# LPC11E6x register map
File version: 0.8
CPU: CM0PLUS r0p1, little endian, no MPU, no FPU, 0x2 interrupt priority bits, 0x0 interrupts
Registers are 32-bit, read-write, reset 0x0 unless marked. A register's access mark holds for its fields unless they carry their own. Offsets are from the block's base; [hi:lo] are bit positions; {n}, {i} and the like mark numbered series.

## SCT0 — State Configurable Timers (SCTimer/PWM)
Base 0x5000C000
Same registers: SCT1 0x5000E000
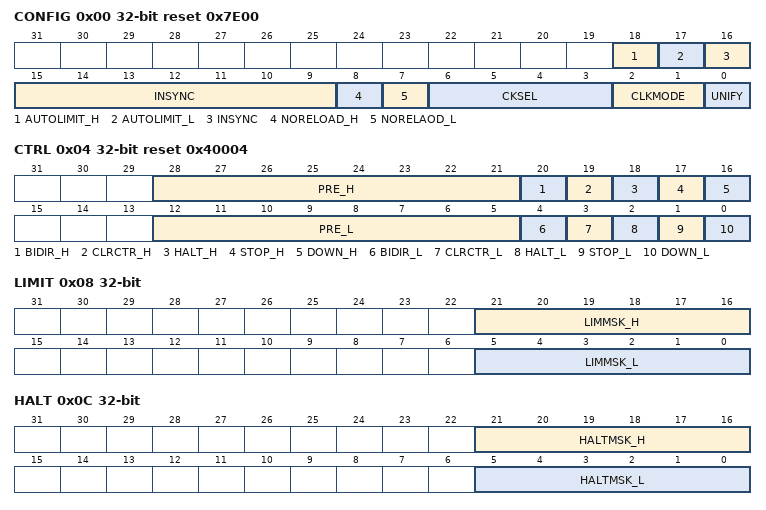
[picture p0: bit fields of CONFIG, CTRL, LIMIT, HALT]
0x00 CONFIG reset 0x7E00 — SCT configuration register
  [18] AUTOLIMIT_H — A one in this bit will cause a match on match register 0 to be treated as a de-facto LIMIT condition without the need to define an associated event. As with any LIMIT event, this automatic limit causes the counter to be cleared to zero in uni-directional mode or to change the direction of count in bi-directional mode. Software can write to set or clear this bit at any time. This bit is not used when the UNIFY bit is set.
  [17] AUTOLIMIT_L — A one in this bit causes a match on match register 0 to be treated as a de-facto LIMIT condition without the need to define an associated event. As with any LIMIT event, this automatic limit causes the counter to be cleared to zero in uni-directional mode or to change the direction of count in bi-directional mode. Software can write to set or clear this bit at any time. This bit applies to both the higher and lower registers when the UNIFY bit is set.
  [16:9] INSYNC — Synchronization for input N (bit 9 = input 0, bit 10 = input 1,..., bit 12 = input 3); all other bits are reserved. A 1 in one of these bits subjects the corresponding input to synchronization to the SCT clock, before it is used to create an event. If an input is synchronous to the SCT clock, keep its bit 0 for faster response. When the CKMODE field is 1x, the bit in this field, corresponding to the input selected by the CKSEL field, is not used.
  [8] NORELOAD_H — A 1 in this bit prevents the higher match registers from being reloaded from their respective reload registers. Software can write to set or clear this bit at any time. This bit is not used when the UNIFY bit is set.
  [7] NORELAOD_L — A 1 in this bit prevents the lower match registers from being reloaded from their respective reload registers. Software can write to set or clear this bit at any time. This bit applies to both the higher and lower registers when the UNIFY bit is set.
  [6:3] CKSEL — SCT clock select
    0=RISING_EDGES_ON_INPU (Rising edges on input 0.); 1=FALLING_EDGES_ON_INP (Falling edges on input 0.); 2=RISING_EDGES_ON_INPU (Rising edges on input 1.); 3=FALLING_EDGES_ON_INP (Falling edges on input 1.); 4=RISING_EDGES_ON_INPU (Rising edges on input 2.); 5=FALLING_EDGES_ON_INP (Falling edges on input 2.); 6=RISING_EDGES_ON_INPU (Rising edges on input 3.); 7=FALLING_EDGES_ON_INP (Falling edges on input 3.)
  [2:1] CLKMODE — SCT clock mode
    0=THE_BUS_CLOCK_CLOCKS (The bus clock clocks the SCT and prescalers.); 1=THE_SCT_CLOCK_IS_THE (The SCT clock is the bus clock, but the prescalers are enabled to count only when sampling of the input selected by the CKSEL field finds the selected edge. The minimum pulse width on the clock input is 1 bus clock period. This mode is the high-performance sampled-clock mode.); 2=THE_INPUT_SELECTED_B (The input selected by CKSEL clocks the SCT and prescalers. The input is synchronized to the bus clock and possibly inverted. The minimum pulse width on the clock input is 1 bus clock period. This mode is the low-power sampled-clock mode.); 3=PRESCALED_SCT_INPUT (Prescaled SCT input. The SCT and prescalers are clocked by the input edge selected by the CKSEL field. In this mode, most of the SCT is clocked by the (selected polarity of the) input. The outputs are switched synchronously to the input clock. The input clock rate must be at least half the system clock rate and can the same or faster than the system clock.)
  [0] UNIFY — SCT operation
    0=THE_SCT_OPERATES_AS (The SCT operates as two 16-bit counters named L and H.); 1=THE_SCT_OPERATES_AS (The SCT operates as a unified 32-bit counter.)
0x04 CTRL reset 0x40004 — SCT control register
  [28:21] PRE_H — Specifies the factor by which the SCT clock is prescaled to produce the H counter clock. The counter clock is clocked at the rate of the SCT clock divided by PRELH+1. Clear the counter (by writing a 1 to the CLRCTR bit) whenever changing the PRE value.
  [20] BIDIR_H — Direction select
    0=THE_H_COUNTER_COUNTS (The H counter counts up to its limit condition, then is cleared to zero.); 1=THE_H_COUNTER_COUNTS (The H counter counts up to its limit, then counts down to a limit condition or to 0.)
  [19] CLRCTR_H — Writing a 1 to this bit clears the H counter. This bit always reads as 0.
  [18] HALT_H — When this bit is 1, the H counter does not run and no events can occur. A reset sets this bit. When the HALT_H bit is one, the STOP_H bit is cleared. If you want to remove the halt condition and keep the SCT in the stop condition (not running), then you can change the halt and stop condition with one single write to this register. Once set, this bit can only be cleared by software to restore counter operation.
  [17] STOP_H — When this bit is 1 and HALT is 0, the H counter does not, run but I/O events related to the counter can occur. If such an event matches the mask in the Start register, this bit is cleared and counting resumes.
  [16] DOWN_H — This bit is 1 when the H counter is counting down. Hardware sets this bit when the counter limit is reached and BIDIR is 1. Hardware clears this bit when the counter is counting down and a limit condition occurs or when the counter reaches 0.
  [12:5] PRE_L — Specifies the factor by which the SCT clock is prescaled to produce the L or unified counter clock. The counter clock is clocked at the rate of the SCT clock divided by PRE_L+1. Clear the counter (by writing a 1 to the CLRCTR bit) whenever changing the PRE value.
  [4] BIDIR_L — L or unified counter direction select
    0=THE_COUNTER_COUNTS_U (The counter counts up to its limit condition, then is cleared to zero.); 1=THE_COUNTER_COUNTS_U (The counter counts up to its limit, then counts down to a limit condition or to 0.)
  [3] CLRCTR_L — Writing a 1 to this bit clears the L or unified counter. This bit always reads as 0.
  [2] HALT_L — When this bit is 1, the L or unified counter does not run and no events can occur. A reset sets this bit. When the HALT_L bit is one, the STOP_L bit is cleared. If you want to remove the halt condition and keep the SCT in the stop condition (not running), then you can change the halt and stop condition with one single write to this register. Once set, only software can clear this bit to restore counter operation.
  [1] STOP_L — When this bit is 1 and HALT is 0, the L or unified counter does not run, but I/O events related to the counter can occur. If such an event matches the mask in the Start register, this bit is cleared and counting resumes.
  [0] DOWN_L — This bit is 1 when the L or unified counter is counting down. Hardware sets this bit when the counter limit is reached and BIDIR is 1. Hardware clears this bit when the counter is counting down and a limit condition occurs or when the counter reaches 0.
0x08 LIMIT — SCT limit register
  [21:16] LIMMSK_H — If bit n is one, event n is used as a counter limit for the H counter (event 0 = bit 16, event 1 = bit 17, event 5 = bit 21).
  [5:0] LIMMSK_L — If bit n is one, event n is used as a counter limit for the L or unified counter (event 0 = bit 0, event 1 = bit 1, event 5 = bit 5).
0x0C HALT — SCT halt condition register
  [21:16] HALTMSK_H — If bit n is one, event n sets the HALT_H bit in the CTRL register (event 0 = bit 16, event 1 = bit 17, event 5 = bit 21).
  [5:0] HALTMSK_L — If bit n is one, event n sets the HALT_L bit in the CTRL register (event 0 = bit 0, event 1 = bit 1, event 5 = bit 5).
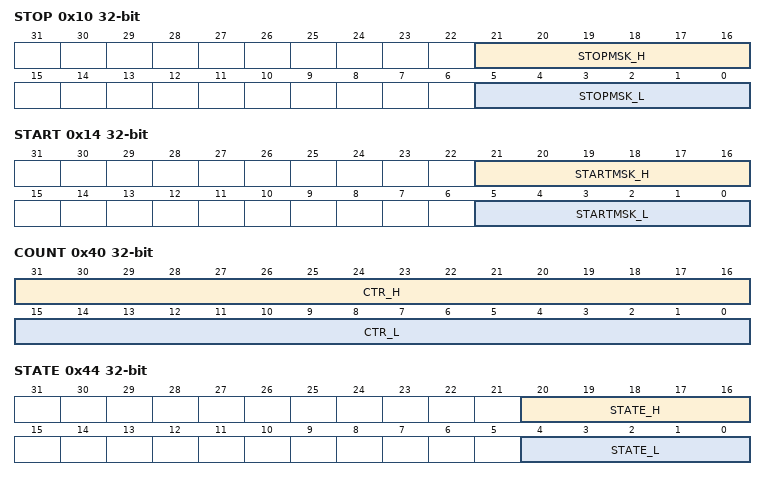
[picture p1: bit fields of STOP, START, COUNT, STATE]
0x10 STOP — SCT stop condition register
  [21:16] STOPMSK_H — If bit n is one, event n sets the STOP_H bit in the CTRL register (event 0 = bit 16, event 1 = bit 17, event 5 = bit 21).
  [5:0] STOPMSK_L — If bit n is one, event n sets the STOP_L bit in the CTRL register (event 0 = bit 0, event 1 = bit 1, event 5 = bit 5).
0x14 START — SCT start condition register
  [21:16] STARTMSK_H — If bit n is one, event n clears the STOP_H bit in the CTRL register (event 0 = bit 16, event 1 = bit 17, event 5 = bit 21).
  [5:0] STARTMSK_L — If bit n is one, event n clears the STOP_L bit in the CTRL register (event 0 = bit 0, event 1 = bit 1, event 5 = bit 5).
0x40 COUNT — SCT counter register
  [31:16] CTR_H — When UNIFY = 0, read or write the 16-bit H counter value. When UNIFY = 1, read or write the upper 16 bits of the 32-bit unified counter.
  [15:0] CTR_L — When UNIFY = 0, read or write the 16-bit L counter value. When UNIFY = 1, read or write the lower 16 bits of the 32-bit unified counter.
0x44 STATE — SCT state register
  [20:16] STATE_H — State variable.
  [4:0] STATE_L — State variable.
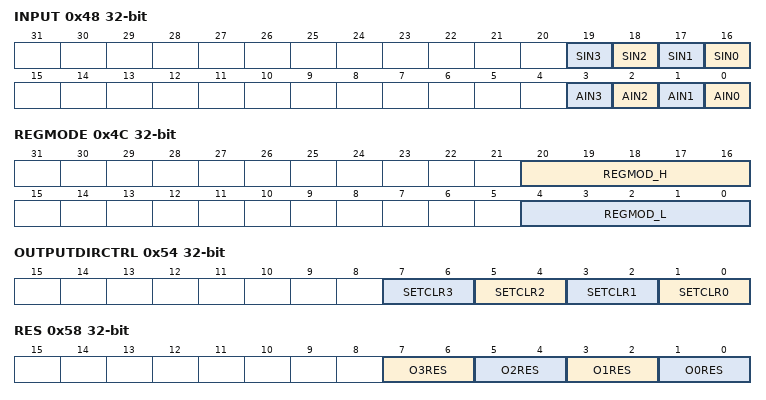
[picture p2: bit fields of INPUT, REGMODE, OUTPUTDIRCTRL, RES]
0x48 INPUT ro — SCT input register
  [n+16] SIN{n} (n=0..3) — Input {n} state synchronized to the SCT clock.
  [n] AIN{n} (n=0..3) — Real-time status of input {n}.
0x4C REGMODE — SCT match/capture registers mode register
  [20:16] REGMOD_H — Each bit controls one pair of match/capture registers (register 0 = bit 16, register 1 = bit 17,..., register 4 = bit 20). 0 = registers operate as match registers. 1 = registers operate as capture registers.
  [4:0] REGMOD_L — Each bit controls one pair of match/capture registers (register 0 = bit 0, register 1 = bit 1,..., register 4 = bit 4). 0 = registers operate as match registers. 1 = registers operate as capture registers.
0x50 OUTPUT — SCT output register
  [3:0] OUT — Writing a 1 to bit n makes the corresponding output HIGH. 0 makes the corresponding output LOW (output 0 = bit 0, output 1 = bit 1,..., output 3 = bit 3).
0x54 OUTPUTDIRCTRL — SCT output counter direction control register
  [all] fields
    0=SET_AND_CLEAR_DO_NOT (Set and clear do not depend on any counter.); 1=SET_AND_CLEAR_ARE_RE (Set and clear are reversed when counter L or the unified counter is counting down.); 2=SET_AND_CLEAR_ARE_RE (Set and clear are reversed when counter H is counting down. Do not use if UNIFY = 1.)
  [2n+1:2n] SETCLR{n} (n=0..3) — Set/clear operation on output {n}. Value 0x3 is reserved. Do not program this value.
0x58 RES — SCT conflict resolution register
  [7:6] O3RES — Effect of simultaneous set and clear on output 3.
    0=NO_CHANGE; 1=SET_OUTPUT_OR_CLEAR (Set output (or clear based on the SETCLR3 field).); 2=CLEAR_OUTPUT_OR_SET (Clear output (or set based on the SETCLR3 field).); 3=TOGGLE_OUTPUT
  [5:4] O2RES — Effect of simultaneous set and clear on output 2.
    0=NO_CHANGE; 1=SET_OUTPUT_OR_CLEAR (Set output (or clear based on the SETCLR2 field).); 2=CLEAR_OUTPUT_N_OR_S (Clear output n (or set based on the SETCLR2 field).); 3=TOGGLE_OUTPUT
  [3:2] O1RES — Effect of simultaneous set and clear on output 1.
    0=NO_CHANGE; 1=SET_OUTPUT_OR_CLEAR (Set output (or clear based on the SETCLR1 field).); 2=CLEAR_OUTPUT_OR_SET (Clear output (or set based on the SETCLR1 field).); 3=TOGGLE_OUTPUT
  [1:0] O0RES — Effect of simultaneous set and clear on output 0.
    0=NO_CHANGE; 1=SET_OUTPUT_OR_CLEAR (Set output (or clear based on the SETCLR0 field).); 2=CLEAR_OUTPUT_OR_SET (Clear output (or set based on the SETCLR0 field).); 3=TOGGLE_OUTPUT
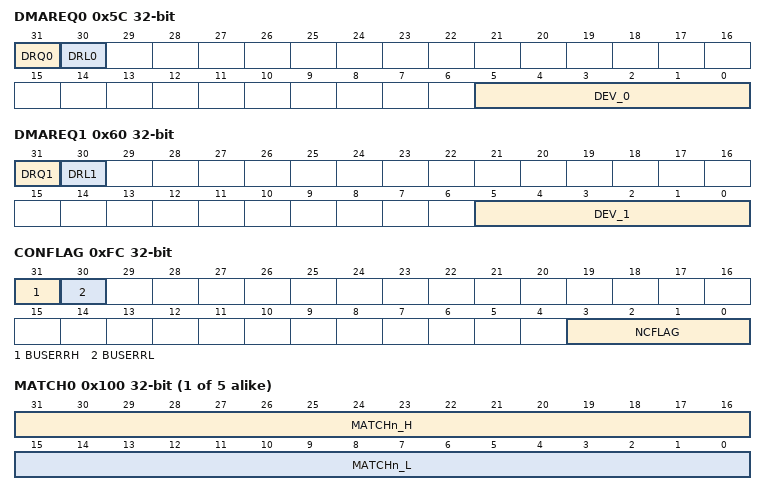
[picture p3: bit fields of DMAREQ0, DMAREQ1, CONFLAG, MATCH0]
0x5C DMAREQ0 — SCT DMA request 0 register
  [31] DRQ0 — This read-only bit indicates the state of DMA Request 0
  [30] DRL0 — A 1 in this bit makes the SCT set DMA request 0 when it loads the Match_L/Unified registers from the Reload_L/Unified registers.
  [5:0] DEV_0 — If bit n is one, event n sets DMA request 0 (event 0 = bit 0, event 1 = bit 1,..., event 5 = bit 5).
0x60 DMAREQ1 — SCT DMA request 1 register
  [31] DRQ1 — This read-only bit indicates the state of DMA Request 1.
  [30] DRL1 — A 1 in this bit makes the SCT set DMA request 1 when it loads the Match L/Unified registers from the Reload L/Unified registers.
  [5:0] DEV_1 — If bit n is one, event n sets DMA request 1 (event 0 = bit 0, event 1 = bit 1,..., event 5 = bit 5).
0xF0 EVEN — SCT event enable register
  [5:0] IEN — The SCT requests interrupt when bit n of this register and the event flag register are both one (event 0 = bit 0, event 1 = bit 1,..., event 5 = bit 5).
0xF4 EVFLAG — SCT event flag register
  [5:0] FLAG — Bit n is one if event n has occurred since reset or a 1 was last written to this bit (event 0 = bit 0, event 1 = bit 1,..., event 5 = bit 5).
0xF8 CONEN — SCT conflict enable register
  [3:0] NCEN — The SCT requests interrupt when bit n of this register and the SCT conflict flag register are both one (output 0 = bit 0, output 1 = bit 1,..., output 3 = bit 3).
0xFC CONFLAG — SCT conflict flag register
  [31] BUSERRH — The most recent bus error from this SCT involved writing CTR H, STATE H, MATCH H, or the Output register when the H counter was not halted.
  [30] BUSERRL — The most recent bus error from this SCT involved writing CTR L/Unified, STATE L/Unified, MATCH L/Unified, or the Output register when the L/U counter was not halted. A word write to certain L and H registers can be half successful and half unsuccessful.
  [3:0] NCFLAG — Bit n is one if a no-change conflict event occurred on output n since reset or a 1 was last written to this bit (output 0 = bit 0, output 1 = bit 1,..., output 3 = bit 3).
{0x100+4i} MATCH{i} (i=0..4) — SCT match value register of match channels 0 to 4; REGMOD0 to REGMODE4 = 0
  [31:16] MATCHn_H — When UNIFY = 0, read or write the 16-bit value to be compared to the H counter. When UNIFY = 1, read or write the upper 16 bits of the 32-bit value to be compared to the unified counter.
  [15:0] MATCHn_L — When UNIFY = 0, read or write the 16-bit value to be compared to the L counter. When UNIFY = 1, read or write the lower 16 bits of the 32-bit value to be compared to the unified counter.
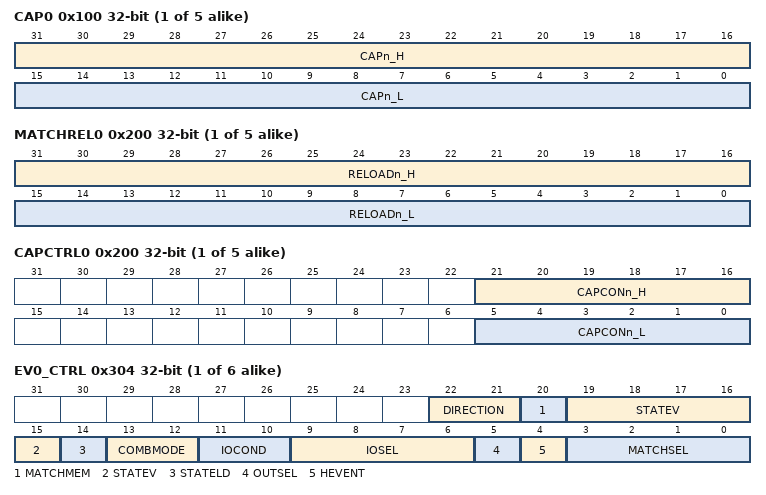
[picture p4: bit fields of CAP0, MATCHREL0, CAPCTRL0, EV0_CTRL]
{0x100+4i} CAP{i} (i=0..4) — SCT capture register of capture channel 0 to 4; REGMOD0 to REGMODE4 = 1
  [31:16] CAPn_H — When UNIFY = 0, read the 16-bit counter value at which this register was last captured. When UNIFY = 1, read the upper 16 bits of the 32-bit value at which this register was last captured.
  [15:0] CAPn_L — When UNIFY = 0, read the 16-bit counter value at which this register was last captured. When UNIFY = 1, read the lower 16 bits of the 32-bit value at which this register was last captured.
{0x200+4i} MATCHREL{i} (i=0..4) — SCT match reload value register 0 to 4; REGMOD0 = 0 to REGMODE4 = 0
  [31:16] RELOADn_H — When UNIFY = 0, read or write the 16-bit to be loaded into the MATCHn_H register. When UNIFY = 1, read or write the upper 16 bits of the 32-bit value to be loaded into the MATCHn register.
  [15:0] RELOADn_L — When UNIFY = 0, read or write the 16-bit value to be loaded into the SCTMATCHn_L register. When UNIFY = 1, read or write the lower 16 bits of the 32-bit value to be loaded into the MATCHn register.
{0x200+4i} CAPCTRL{i} (i=0..4) — SCT capture control register 0 to 4; REGMOD0 = 1 to REGMODE4 = 1
  [21:16] CAPCONn_H — If bit m is one, event m causes the CAPn_H (UNIFY = 0) register to be loaded (event 0 = bit 16, event 1 = bit 17,..., event 5 = bit 21).
  [5:0] CAPCONn_L — If bit m is one, event m causes the CAPn_L (UNIFY = 0) or the CAPn (UNIFY = 1) register to be loaded (event 0 = bit 0, event 1 = bit 1,..., event 5 = bit 5).
{0x300+8i} EV{i}_STATE (i=0..5) — SCT event state register 0
  [7:0] STATEMSKn — If bit m is one, event n (n= 0 to 5) happens in state m of the counter selected by the HEVENT bit (m = state number; state 0 = bit 0, state 1= bit 1,..., state 7 = bit 7).
{0x304+8i} EV{i}_CTRL (i=0..5) — SCT event control register 0
  [22:21] DIRECTION — Direction qualifier for event generation. This field only applies when the counters are operating in BIDIR mode. If BIDIR = 0, the SCT ignores this field. Value 0x3 is reserved.
    0=DIRECTION_INDEPENDEN (Direction independent. This event is triggered regardless of the count direction.); 1=COUNTING_UP (Counting up. This event is triggered only during up-counting when BIDIR = 1.); 2=COUNTING_DOWN (Counting down. This event is triggered only during down-counting when BIDIR = 1.)
  [20] MATCHMEM — If this bit is one and the COMBMODE field specifies a match component to the triggering of this event, then a match is considered to be active whenever the counter value is GREATER THAN OR EQUAL TO the value specified in the match register when counting up, LESS THEN OR EQUAL TO the match value when counting down. If this bit is zero, a match is only be active during the cycle when the counter is equal to the match value.
  [19:15] STATEV — This value is loaded into or added to the state selected by HEVENT, depending on STATELD, when this event is the highest-numbered event occurring for that state. If STATELD and STATEV are both zero, there is no change to the STATE value.
  [14] STATELD — This bit controls how the STATEV value modifies the state selected by HEVENT when this event is the highest-numbered event occurring for that state.
    0=STATEV_VALUE_IS_ADDE (STATEV value is added into STATE (the carry-out is ignored).); 1=STATEV_VALUE_IS_LOAD (STATEV value is loaded into STATE.)
  [13:12] COMBMODE — Selects how the specified match and I/O condition are used and combined.
    0=OR (OR. The event occurs when either the specified match or I/O condition occurs.); 1=MATCH (MATCH. Uses the specified match only.); 2=IO (IO. Uses the specified I/O condition only.); 3=AND (AND. The event occurs when the specified match and I/O condition occur simultaneously.)
  [11:10] IOCOND — Selects the I/O condition for event n. (The detection of edges on outputs lag the conditions that switch the outputs by one SCT clock). In order to guarantee proper edge/state detection, an input must have a minimum pulse width of at least one SCT clock period .
    0=LOW; 1=RISE; 2=FALL; 3=HIGH
  [9:6] IOSEL — Selects the input or output signal number (0 to 3) associated with this event (if any). Do not select an input in this register, if CKMODE is 1x. In this case the clock input is an implicit ingredient of every event.
  [5] OUTSEL — Input/output select
    0=SELECTS_THE_INPUTS_E (Selects the inputs elected by IOSEL.); 1=SELECTS_THE_OUTPUTS (Selects the outputs selected by IOSEL.)
  [4] HEVENT — Select L/H counter. Do not set this bit if UNIFY = 1.
    0=SELECTS_THE_L_STATE (Selects the L state and the L match register selected by MATCHSEL.); 1=SELECTS_THE_H_STATE (Selects the H state and the H match register selected by MATCHSEL.)
  [3:0] MATCHSEL — Selects the Match register associated with this event (if any). A match can occur only when the counter selected by the HEVENT bit is running.
{0x500+8i} OUT{i}_SET (i=0..3) — SCT output 0 set register
  [5:0] SET — A 1 in bit m selects event m to set output n (or clear it if SETCLRn = 0x1 or 0x2) event 0 = bit 0, event 1 = bit 1,..., event 5 = bit 5.
{0x504+8i} OUT{i}_CLR (i=0..3) — SCT output 0 clear register
  [5:0] CLR — A 1 in bit m selects event m to clear output n (or set it if SETCLRn = 0x1 or 0x2) event 0 = bit 0, event 1 = bit 1,..., event 5 = bit 5.
